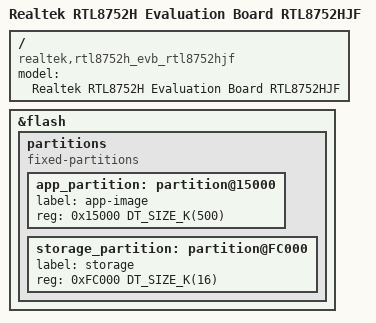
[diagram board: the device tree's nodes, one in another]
/*
 * Copyright (c) 2026, Realtek Semiconductor Corporation.
 *
 * SPDX-License-Identifier: Apache-2.0
 */

/dts-v1/;
#include <realtek/bee/rtl8752hjf.dtsi>
#include "rtl8752h_evb.dtsi"

/ {
	model = "Realtek RTL8752H Evaluation Board RTL8752HJF";
	compatible = "realtek,rtl8752h_evb_rtl8752hjf";
};

&flash {
	partitions {
		compatible = "fixed-partitions";
		#address-cells = <1>;
		#size-cells = <1>;

		app_partition: partition@15000 {
			label = "app-image";
			reg = <0x15000 DT_SIZE_K(500)>;
		};

		storage_partition: partition@FC000 {
			label = "storage";
			reg = <0xFC000 DT_SIZE_K(16)>;
		};
	};
};
